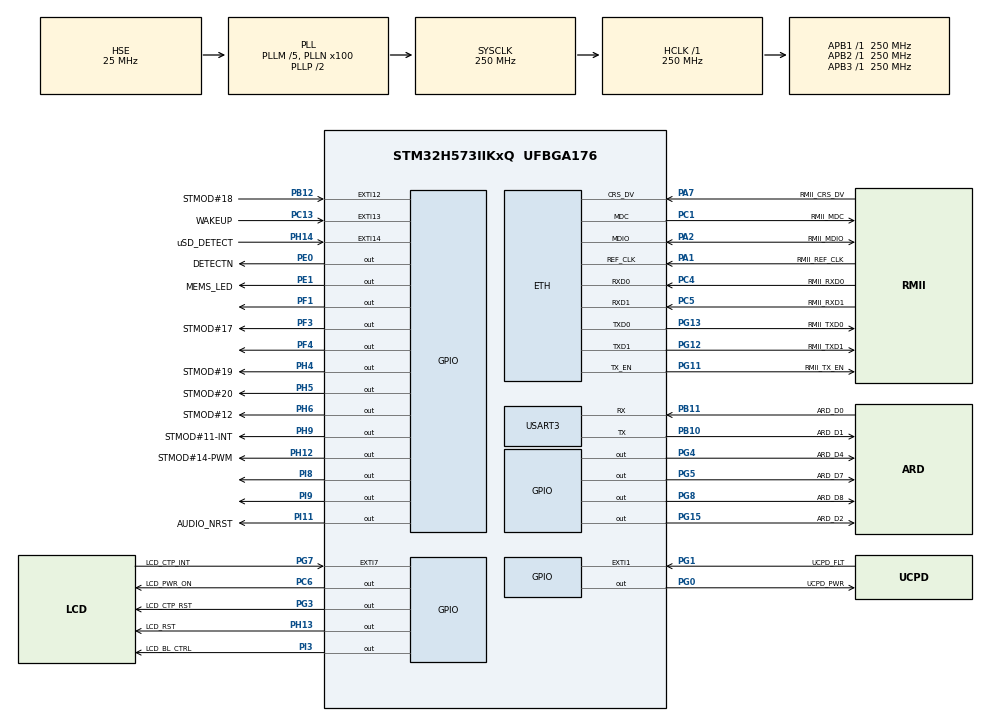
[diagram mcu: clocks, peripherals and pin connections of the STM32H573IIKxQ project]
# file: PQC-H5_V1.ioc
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AES.Algorithm=CRYP_AES_ECB
AES.KeySize=CRYP_KEYSIZE_256B
BOOTPATH.BootPathName=LEGACY
BOOTPATH.UserSelectedBootPath=LEGACY
CORTEX_M33_NS.userName=CORTEX_M33
ETH.MediaInterface=HAL_ETH_RMII_MODE
ETH.RxBuffLen=1536
HASH.Algorithm=HASH_ALGOSELECTION_SHA384
HASH.pKey=__NULL
Mcu.Family=STM32H5
Mcu.Name=STM32H573IIKxQ
Mcu.Package=UFBGA176
NETXDUO.ETH_ON=1
NETXDUO.LAN_8742=1
NETXDUO.NX_APP_MEM_POOL_SIZE=1024*100
NETXDUO.NX_APP_PACKET_POOL_SIZE=20
NETXDUO.NetXDuo_Generate_Init_Code=true
NVIC.PriorityGroup=NVIC_PRIORITYGROUP_4
NVIC.TIM6_IRQn=true\:15\:0\:false\:false\:true\:false\:false\:true\:true
NVIC.TimeBase=TIM6_IRQn
NVIC.TimeBaseIP=TIM6
NetXDuo.BSP.number=1
NetXDuo0.BSP.STBoard=false
NetXDuo0.BSP.api=BSP_COMPONENT_DRIVER
NetXDuo0.BSP.component=lan8742
NetXDuo0.BSP.instance=lan8742
NetXDuo0.BSP.name=LAN_Component
NetXDuo0.BSP.semaphore=SEMA_lan8742
NetXDuo0.BSP.solution=lan8742
PA0.GPIO_Label=ARD_A2
PA0.Signal=ADCx_INP0
PA1.GPIO_Label=RMII_REF_CLK
PA1.Mode=RMII
PA1.Signal=ETH_REF_CLK
PA10.Signal=USART1_RX
PA11.GPIO_Label=USB_FS_N
PA11.Signal=USB_DM
PA12.GPIO_Label=USB_FS_P
PA12.Signal=USB_DP
PA13(JTMS/SWDIO).GPIO_Label=JTMS
PA13(JTMS/SWDIO).Signal=DEBUG_JTMS-SWDIO
PA14(JTCK/SWCLK).GPIO_Label=JTCK
PA14(JTCK/SWCLK).Signal=DEBUG_JTCK-SWCLK
PA15(JTDI).GPIO_Label=JTDI
PA15(JTDI).Signal=DEBUG_JTDI
PA2.GPIO_Label=RMII_MDIO
PA2.Mode=RMII
PA2.Signal=ETH_MDIO
PA3.GPIO_Label=ARD_D10
PA3.Signal=SPI2_NSS
PA4.GPIO_Label=ARD_A1
PA4.Signal=ADCx_INP18
PA5.GPIO_Label=ARD_A3
PA5.Signal=ADCx_INP19
PA6.GPIO_Label=ARD_A4
PA6.Signal=ADCx_INP3
PA7.GPIO_Label=RMII_CRS_DV
PA7.Mode=RMII
PA7.Signal=ETH_CRS_DV
PA8.GPIO_Label=ARD_D9
PA8.Signal=S_TIM1_CH1
PA9.Signal=USART1_TX
PB0.GPIO_Label=ARD_A0
PB0.Signal=ADCx_INP9
PB1.GPIO_Mode=GPIO_MODE_AF_PP
PB1.GPIO_PuPd=GPIO_NOPULL
PB1.GPIO_Speed_High_Default=GPIO_SPEED_FREQ_VERY_HIGH
PB1.Signal=OCTOSPI1_IO0
PB10.GPIO_Label=ARD_D1
PB10.Mode=Asynchronous
PB10.Signal=USART3_TX
PB11.GPIO_Label=ARD_D0
PB11.Mode=Asynchronous
PB11.Signal=USART3_RX
PB12.GPIO_Label=STMOD\#18
PB12.Signal=GPXTI12
PB13.GPIO_Label=UCPD_CC1
PB13.Signal=UCPD1_CC1
PB14.GPIO_Label=UCPD_CC2
PB14.Signal=UCPD1_CC2
PB15.GPIO_Label=ARD_D11
PB15.Signal=SPI2_MOSI
PB2.Signal=OCTOSPI1_DQS
PB3(JTDO/TRACESWO).GPIO_Label=SWO
PB3(JTDO/TRACESWO).Signal=DEBUG_JTDO-SWO
PB5.GPIO_Label=ARD_D3
PB5.Signal=S_TIM3_CH2
PB6.GPIO_Label=I2C1_SCL
PB6.Signal=I2C1_SCL
PB7.GPIO_Label=I2C1_SDA
PB7.Signal=I2C1_SDA
PC0.Signal=OCTOSPI1_IO7
PC1.GPIO_Label=RMII_MDC
PC1.Mode=RMII
PC1.Signal=ETH_MDC
PC10.GPIO_Label=SDIO1_D2
PC10.Signal=SDMMC1_D2
PC11.GPIO_Label=SDIO1_D3
PC11.Signal=SDMMC1_D3
PC12.GPIO_Label=SDIO1_CK
PC12.Signal=SDMMC1_CK
PC13.GPIO_Label=WAKEUP
PC13.Signal=GPXTI13
PC14-OSC32_IN(OSC32_IN).Signal=RCC_OSC32_IN
PC15-OSC32_OUT(OSC32_OUT).Signal=RCC_OSC32_OUT
PC2.GPIO_Mode=GPIO_MODE_AF_PP
PC2.GPIO_PuPd=GPIO_NOPULL
PC2.GPIO_Speed_High_Default=GPIO_SPEED_FREQ_VERY_HIGH
PC2.Signal=OCTOSPI1_IO2
PC3.GPIO_Label=PDM_SAI1_SD3
PC3.Signal=SAI1_D3
PC4.GPIO_Label=RMII_RXD0
PC4.Mode=RMII
PC4.Signal=ETH_RXD0
PC5.GPIO_Label=RMII_RXD1
PC5.Mode=RMII
PC5.Signal=ETH_RXD1
PC6.GPIO_Label=LCD_PWR_ON
PC6.Signal=GPIO_Output
PC7.Signal=FMC_NE1
PC8.GPIO_Label=SDIO1_D0
PC8.Signal=SDMMC1_D0
PC9.GPIO_Label=SDIO1_D1
PC9.Signal=SDMMC1_D1
PD0.GPIO_Label=LCD_D2
PD0.Signal=FMC_D2_DA2
PD1.GPIO_Label=LCD_D3
PD1.Signal=FMC_D3_DA3
PD10.GPIO_Label=LCD_D15
PD10.Signal=FMC_D15_DA15
PD11.Signal=SAI1_CK1
PD12.GPIO_Mode=GPIO_MODE_AF_PP
PD12.GPIO_PuPd=GPIO_NOPULL
PD12.GPIO_Speed_High_Default=GPIO_SPEED_FREQ_VERY_HIGH
PD12.Signal=OCTOSPI1_IO1
PD13.GPIO_Mode=GPIO_MODE_AF_PP
PD13.GPIO_PuPd=GPIO_NOPULL
PD13.GPIO_Speed_High_Default=GPIO_SPEED_FREQ_VERY_HIGH
PD13.Signal=OCTOSPI1_IO3
PD14.GPIO_Label=LCD_D0
PD14.Signal=FMC_D0_DA0
PD15.GPIO_Label=LCD_D1
PD15.Signal=FMC_D1_DA1
PD2.GPIO_Label=SDIO1_CMD
PD2.Signal=SDMMC1_CMD
PD3.GPIO_Label=LCD_TE
PD3.Signal=FMC_CLK
PD4.GPIO_Label=LCD_NOE
PD4.Signal=FMC_NOE
PD5.GPIO_Label=LCD_NWE
PD5.Signal=FMC_NWE
PD6.Signal=SAI1_SD_A
PD8.GPIO_Label=LCD_D13
PD8.Signal=FMC_D13_DA13
PD9.GPIO_Label=LCD_D14
PD9.Signal=FMC_D14_DA14
PE0.GPIO_Label=DETECTN
PE0.Signal=GPIO_Output
PE1.GPIO_Label=MEMS_LED
PE1.Signal=GPIO_Output
PE10.GPIO_Label=LCD_D7
PE10.Signal=FMC_D7_DA7
PE11.GPIO_Label=LCD_D8
PE11.Signal=FMC_D8_DA8
PE12.GPIO_Label=LCD_D9
PE12.Signal=FMC_D9_DA9
PE13.GPIO_Label=LCD_D10
PE13.Signal=FMC_D10_DA10
PE14.GPIO_Label=LCD_D11
PE14.Signal=FMC_D11_DA11
PE15.GPIO_Label=LCD_D12
PE15.Signal=FMC_D12_DA12
PE2.Signal=DEBUG_TRACECLK
PE3.GPIO_Label=TRACED0
PE3.Signal=DEBUG_TRACED0
PE4.Signal=SAI1_D2
PE5.GPIO_Label=TRACED2
PE5.Signal=DEBUG_TRACED2
PE6.GPIO_Label=TRACED3
PE6.Signal=DEBUG_TRACED3
PE7.Signal=FMC_D4_DA4
PE8.GPIO_Label=LCD_D5
PE8.Signal=FMC_D5_DA5
PE9.GPIO_Label=LCD_D6
PE9.Signal=FMC_D6_DA6
PF0.GPIO_Label=LCD_A0_RS
PF0.Signal=FMC_A0
PF1.Signal=GPIO_Output
PF10.GPIO_Mode=GPIO_MODE_AF_PP
PF10.GPIO_PuPd=GPIO_NOPULL
PF10.GPIO_Speed_High_Default=GPIO_SPEED_FREQ_VERY_HIGH
PF10.Signal=OCTOSPI1_CLK
PF11.GPIO_Label=STMOD\#13
PF11.Signal=ADC1_INP2
PF12.GPIO_Label=ARD_A5
PF12.Signal=ADC1_INP6
PF13.GPIO_Label=IBUS_SENSE
PF13.Signal=ADC2_INP2
PF14.GPIO_Label=VBUS_SENSE
PF14.Signal=ADC2_INP6
PF3.GPIO_Label=STMOD\#17
PF3.Signal=GPIO_Output
PF4.Signal=GPIO_Output
PG0.GPIO_Label=UCPD_PWR
PG0.Signal=GPIO_Output
PG1.GPIO_Label=UCPD_FLT
PG1.Signal=GPXTI1
PG10.GPIO_Label=SAI2_SD_B
PG10.Signal=SAI2_SD_B
PG11.GPIO_Label=RMII_TX_EN
PG11.Mode=RMII
PG11.Signal=ETH_TX_EN
PG12.GPIO_Label=RMII_TXD1
PG12.Mode=RMII
PG12.Signal=ETH_TXD1
PG13.GPIO_Label=RMII_TXD0
PG13.Mode=RMII
PG13.Signal=ETH_TXD0
PG14.GPIO_Label=TRACED1
PG14.Signal=DEBUG_TRACED1
PG15.GPIO_Label=ARD_D2
PG15.Signal=GPIO_Output
PG3.GPIO_Label=LCD_CTP_RST
PG3.Signal=GPIO_Output
PG4.GPIO_Label=ARD_D4
PG4.Signal=GPIO_Output
PG5.GPIO_Label=ARD_D7
PG5.Signal=GPIO_Output
PG6.GPIO_Mode=GPIO_MODE_AF_PP
PG6.GPIO_PuPd=GPIO_NOPULL
PG6.GPIO_Speed_High_Default=GPIO_SPEED_FREQ_VERY_HIGH
PG6.Signal=OCTOSPI1_NCS
PG7.GPIO_Label=LCD_CTP_INT
PG7.Signal=GPXTI7
PG8.GPIO_Label=ARD_D8
PG8.Signal=GPIO_Output
PG9.GPIO_Mode=GPIO_MODE_AF_PP
PG9.GPIO_PuPd=GPIO_NOPULL
PG9.GPIO_Speed_High_Default=GPIO_SPEED_FREQ_VERY_HIGH
PG9.Signal=OCTOSPI1_IO6
PH0-OSC_IN(PH0).Mode=HSE-DIG-External-Clock-Source
PH0-OSC_IN(PH0).Signal=RCC_OSC_IN
PH10.GPIO_Label=ARD_D6
PH10.Signal=S_TIM5_CH1
PH11.GPIO_Label=ARD_D5
PH11.Signal=S_TIM5_CH2
PH12.GPIO_Label=STMOD\#14-PWM
PH12.Signal=GPIO_Output
PH13.GPIO_Label=LCD_RST
PH13.Signal=GPIO_Output
PH14.GPIO_Label=uSD_DETECT
PH14.Signal=GPXTI14
PH2.GPIO_Mode=GPIO_MODE_AF_PP
PH2.GPIO_PuPd=GPIO_NOPULL
PH2.GPIO_Speed_High_Default=GPIO_SPEED_FREQ_VERY_HIGH
PH2.Signal=OCTOSPI1_IO4
PH3.GPIO_Mode=GPIO_MODE_AF_PP
PH3.GPIO_PuPd=GPIO_NOPULL
PH3.GPIO_Speed_High_Default=GPIO_SPEED_FREQ_VERY_HIGH
PH3.Signal=OCTOSPI1_IO5
PH4.GPIO_Label=STMOD\#19
PH4.Signal=GPIO_Output
PH5.GPIO_Label=STMOD\#20
PH5.Signal=GPIO_Output
PH6.GPIO_Label=STMOD\#12
PH6.Signal=GPIO_Output
PH7.GPIO_Label=STMOD\#12-RST
PH7.Signal=SPI5_MISO
PH8.GPIO_Label=STMOD\#9-MISOs
PH8.Signal=SPI5_MOSI
PH9.GPIO_Label=STMOD\#11-INT
PH9.Signal=GPIO_Output
PI1.GPIO_Label=ARD_D13
PI1.Signal=SPI2_SCK
PI10.GPIO_Label=RMII_RX_ER
PI10.Signal=ETH_RX_ER
PI11.GPIO_Label=AUDIO_NRST
PI11.Signal=GPIO_Output
PI2.GPIO_Label=ARD_D12
PI2.Signal=SPI2_MISO
PI3.GPIO_Label=LCD_BL_CTRL
PI3.Signal=GPIO_Output
PI4.GPIO_Label=SAI2_MCLK_A
PI4.Signal=SAI2_MCLK_A
PI5.GPIO_Label=SAI2_SCK_A
PI5.Signal=SAI2_SCK_A
PI6.GPIO_Label=SAI2_SD_A
PI6.Signal=SAI2_SD_A
PI7.GPIO_Label=SAI2_FS_A
PI7.Signal=SAI2_FS_A
PI8.Signal=GPIO_Output
PI9.Signal=GPIO_Output
ProjectManager.HeapSize=0x800
ProjectManager.StackSize=0x1000
ProjectManager.TargetToolchain=STM32CubeIDE
RCC.ADCFreq_Value=250000000
RCC.AHBFreq_Value=250000000
RCC.APB1Freq_Value=250000000
RCC.APB1TimFreq_Value=250000000
RCC.APB2Freq_Value=250000000
RCC.APB2TimFreq_Value=250000000
RCC.APB3Freq_Value=250000000
RCC.CSI_VALUE=4000000
RCC.CortexFreq_Value=250000000
RCC.EPOD_VALUE=25000000
RCC.HCLKFreq_Value=250000000
RCC.HSE_VALUE=25000000
RCC.HSI48_VALUE=48000000
RCC.HSIDiv=RCC_HSI_DIV1
RCC.HSI_VALUE=64000000
RCC.LSE_VALUE=32768
RCC.LSIRC_VALUE=32000
RCC.PLL2FRACN=0
RCC.PLL2N=32
RCC.PLL2P=1
RCC.PLLM=5
RCC.PLLN=100
RCC.PLLSourceVirtual=RCC_PLL1_SOURCE_HSE
RCC.SYSCLKFreq_VALUE=250000000
RCC.SYSCLKSource=RCC_SYSCLKSOURCE_PLLCLK
RCC.USBFreq_Value=48000000
RCC.VCOOutputFreq_Value=500000000
SH.ADCx_INP0.0=ADC1_INP0
SH.ADCx_INP18.0=ADC1_INP18
SH.ADCx_INP19.0=ADC1_INP19
SH.ADCx_INP3.0=ADC1_INP3
SH.ADCx_INP9.0=ADC1_INP9
SH.FMC_A0.0=FMC_A0
SH.FMC_CLK.0=FMC_CLK
SH.FMC_D0_DA0.0=FMC_D0
SH.FMC_D10_DA10.0=FMC_D10
SH.FMC_D11_DA11.0=FMC_D11
SH.FMC_D12_DA12.0=FMC_D12
SH.FMC_D13_DA13.0=FMC_D13
SH.FMC_D14_DA14.0=FMC_D14
SH.FMC_D15_DA15.0=FMC_D15
SH.FMC_D1_DA1.0=FMC_D1
SH.FMC_D2_DA2.0=FMC_D2
SH.FMC_D3_DA3.0=FMC_D3
SH.FMC_D4_DA4.0=FMC_D4
SH.FMC_D5_DA5.0=FMC_D5
SH.FMC_D6_DA6.0=FMC_D6
SH.FMC_D7_DA7.0=FMC_D7
SH.FMC_D8_DA8.0=FMC_D8
SH.FMC_D9_DA9.0=FMC_D9
SH.FMC_NOE.0=FMC_NOE
SH.FMC_NWE.0=FMC_NWE
SH.S_TIM1_CH1.0=TIM1_CH1
SH.S_TIM3_CH2.0=TIM3_CH2
SH.S_TIM5_CH1.0=TIM5_CH1
SH.S_TIM5_CH2.0=TIM5_CH2
STM32H573I-DK.LD1=true
STM32H573I-DK.LD2=true
STM32H573I-DK.LD3=true
STM32H573I-DK.LD4=true
STM32H573I-DK.VCP=true
STMicroelectronics.X-CUBE-FREERTOS.1.3.1.configTOTAL_HEAP_SIZE=50000
THREADX.TX_APP_CREATION=1
THREADX.TX_APP_GENERATE_INIT_CODE=true
THREADX.TX_APP_MEM_POOL_SIZE=1024*10
THREADX.TX_APP_STACK_SIZE=1024
USART3.VirtualMode-Asynchronous=VM_ASYNC
VP_AES_VS_AES.Mode=AES_Activate
VP_BOOTPATH_VS_BOOTPATH.Mode=BP_Activate
VP_CORTEX_M33_NS_VS_Hclk.Mode=Hclk_Mode
VP_HASH_VS_HASH.Mode=HASH_Activate
VP_ICACHE_VS_ENABLE_ICACHE_MEMORY.Mode=Memoryregions
VP_ICACHE_VS_ICACHE.Mode=DefaultMode
VP_MEMORYMAP_VS_MEMORYMAP.Mode=CurAppReg
VP_NETXDUO_VS_AddonsOoDHCP.Mode=Addons_DHCP_Client
VP_NETXDUO_VS_EthernetOoPhyOoInterface.Mode=LAN8742_Phy_Interface
VP_NETXDUO_VS_NXOoCore.Mode=NX_Core
VP_NETXDUO_VS_NetworkOoInterface.Mode=Ethernet_Interface
VP_PWR_VS_LPOM.Mode=PowerOptimisation
VP_PWR_VS_SECSignals.Mode=Security/Privilege
VP_RNG_VS_RNG.Mode=RNG_Activate
VP_RTC_VS_RTC_Activate.Mode=RTC_Enabled
VP_RTC_VS_RTC_Calendar.Mode=RTC_Calendar
VP_STM32H573I-DK_VS_BSP_COMMON.Mode=COMMON
VP_SYS_VS_tim6.Mode=TIM6
VP_THREADX_VS_RTOSJjThreadXJjCoreJjDefault.Mode=Core_Default
VP_wolfSSL.I-CUBE-wolfSSL_VS_wolfSSLJjwolfSSL_5.8.0_5.8.0.Mode=wolfSSLJjwolfSSL
board=STM32H573I-DK
wolfSSL.I-CUBE-wolfSSL.5.8.0.WOLF_CONF_KYBER=1
wolfSSL.I-CUBE-wolfSSL.5.8.0.WOLF_CONF_MATH=4
wolfSSL.I-CUBE-wolfSSL.5.8.0.WOLF_CONF_SHA2_384=1
wolfSSL.I-CUBE-wolfSSL.5.8.0.WOLF_CONF_SHA2_512=1
wolfSSL.I-CUBE-wolfSSL.5.8.0.WOLF_CONF_SHA3=1
wolfSSL.I-CUBE-wolfSSL.5.8.0.wolfSSLCcwolfSSLJjwolfCryptJjCore=true
wolfSSL.I-CUBE-wolfSSL.5.8.0.wolfSSLCcwolfSSLJjwolfCryptJjTest=true
wolfSSL.I-CUBE-wolfSSL.5.8.0.wolfSSLCcwolfSSLJjwolfSSLJjCore=true

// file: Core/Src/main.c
/* USER CODE BEGIN Header */
/**
  ******************************************************************************
  * @file           : main.c
  * @brief          : Main program body
  ******************************************************************************
  * @attention
  *
  * Copyright (c) 2025 STMicroelectronics.
  * All rights reserved.
  *
  * This software is licensed under terms that can be found in the LICENSE file
  * in the root directory of this software component.
  * If no LICENSE file comes with this software, it is provided AS-IS.
  *
  ******************************************************************************
  */
/* USER CODE END Header */
#include "app_threadx.h"
#include "main.h"

/* USER CODE BEGIN Includes */
#include "wolfssl/wolfcrypt/settings.h"
//#include "wolfssl_example.h"
/* USER CODE END Includes */

ETH_DMADescTypeDef  DMARxDscrTab[ETH_RX_DESC_CNT]; /* Ethernet Rx DMA Descriptors */
ETH_DMADescTypeDef  DMATxDscrTab[ETH_TX_DESC_CNT]; /* Ethernet Tx DMA Descriptors */

COM_InitTypeDef BspCOMInit;
CRYP_HandleTypeDef hcryp;
uint32_t pKeyAES[8] = {0x00000000,0x00000000,0x00000000,0x00000000,0x00000000,0x00000000,0x00000000,0x00000000};

ETH_HandleTypeDef heth;

HASH_HandleTypeDef hhash;

RNG_HandleTypeDef hrng;

RTC_HandleTypeDef hrtc;

UART_HandleTypeDef huart3;

/* USER CODE BEGIN PV */
__ALIGN_BEGIN static const uint32_t pKeyCRYP[6] __ALIGN_END = {
            0x00000000,0x00000000,0x00000000,0x00000000,0x00000000,0x00000000};
/* USER CODE END PV */

void SystemClock_Config(void);
static void MX_GPIO_Init(void);
static void MX_ICACHE_Init(void);
static void MX_RNG_Init(void);
static void MX_RTC_Init(void);
static void MX_HASH_Init(void);
static void MX_AES_Init(void);
static void MX_USART3_UART_Init(void);
static void MX_ETH_Init(void);

int main(void)
{

  /* MCU Configuration--------------------------------------------------------*/

  /* Reset of all peripherals, Initializes the Flash interface and the Systick. */
  HAL_Init();

  /* USER CODE BEGIN Init */
  setvbuf(stdin, NULL, _IONBF, 0);
  setvbuf(stdout, NULL, _IONBF, 0);
  setvbuf(stderr, NULL, _IONBF, 0);
  /* USER CODE END Init */

  /* Configure the system clock */
  SystemClock_Config();

  /* Initialize all configured peripherals */
  MX_GPIO_Init();
  MX_ICACHE_Init();
  MX_RNG_Init();
  MX_RTC_Init();
  MX_HASH_Init();
  MX_AES_Init();
  MX_USART3_UART_Init();
  MX_ETH_Init();

  /* Initialize leds */
  BSP_LED_Init(LED_GREEN);
  BSP_LED_Init(LED_ORANGE);
  BSP_LED_Init(LED_RED);
  BSP_LED_Init(LED_BLUE);

  /* Initialize COM1 port (115200, 8 bits (7-bit data + 1 stop bit), no parity */
  BspCOMInit.BaudRate   = 115200;
  BspCOMInit.WordLength = COM_WORDLENGTH_8B;
  BspCOMInit.StopBits   = COM_STOPBITS_1;
  BspCOMInit.Parity     = COM_PARITY_NONE;
  BspCOMInit.HwFlowCtl  = COM_HWCONTROL_NONE;
  if (BSP_COM_Init(COM1, &BspCOMInit) != BSP_ERROR_NONE)
  {
    Error_Handler();
  }

  MX_ThreadX_Init();

  /* We should never get here as control is now taken by the scheduler */

  /* Infinite loop */
  while (1)
  {

  }
}

void SystemClock_Config(void)
{
  RCC_OscInitTypeDef RCC_OscInitStruct = {0};
  RCC_ClkInitTypeDef RCC_ClkInitStruct = {0};

  /** Configure the main internal regulator output voltage
  */
  __HAL_PWR_VOLTAGESCALING_CONFIG(PWR_REGULATOR_VOLTAGE_SCALE0);

  while(!__HAL_PWR_GET_FLAG(PWR_FLAG_VOSRDY)) {}

  /** Initializes the RCC Oscillators according to the specified parameters
  * in the RCC_OscInitTypeDef structure.
  */
  RCC_OscInitStruct.OscillatorType = RCC_OSCILLATORTYPE_HSI48|RCC_OSCILLATORTYPE_LSI
                              |RCC_OSCILLATORTYPE_HSE;
  RCC_OscInitStruct.HSEState = RCC_HSE_BYPASS_DIGITAL;
  RCC_OscInitStruct.LSIState = RCC_LSI_ON;
  RCC_OscInitStruct.HSI48State = RCC_HSI48_ON;
  RCC_OscInitStruct.PLL.PLLState = RCC_PLL_ON;
  RCC_OscInitStruct.PLL.PLLSource = RCC_PLL1_SOURCE_HSE;
  RCC_OscInitStruct.PLL.PLLM = 5;
  RCC_OscInitStruct.PLL.PLLN = 100;
  RCC_OscInitStruct.PLL.PLLP = 2;
  RCC_OscInitStruct.PLL.PLLQ = 2;
  RCC_OscInitStruct.PLL.PLLR = 2;
  RCC_OscInitStruct.PLL.PLLRGE = RCC_PLL1_VCIRANGE_2;
  RCC_OscInitStruct.PLL.PLLVCOSEL = RCC_PLL1_VCORANGE_WIDE;
  RCC_OscInitStruct.PLL.PLLFRACN = 0;
  if (HAL_RCC_OscConfig(&RCC_OscInitStruct) != HAL_OK)
  {
    Error_Handler();
  }

  /** Initializes the CPU, AHB and APB buses clocks
  */
  RCC_ClkInitStruct.ClockType = RCC_CLOCKTYPE_HCLK|RCC_CLOCKTYPE_SYSCLK
                              |RCC_CLOCKTYPE_PCLK1|RCC_CLOCKTYPE_PCLK2
                              |RCC_CLOCKTYPE_PCLK3;
  RCC_ClkInitStruct.SYSCLKSource = RCC_SYSCLKSOURCE_PLLCLK;
  RCC_ClkInitStruct.AHBCLKDivider = RCC_SYSCLK_DIV1;
  RCC_ClkInitStruct.APB1CLKDivider = RCC_HCLK_DIV1;
  RCC_ClkInitStruct.APB2CLKDivider = RCC_HCLK_DIV1;
  RCC_ClkInitStruct.APB3CLKDivider = RCC_HCLK_DIV1;

  if (HAL_RCC_ClockConfig(&RCC_ClkInitStruct, FLASH_LATENCY_5) != HAL_OK)
  {
    Error_Handler();
  }

  /** Configure the programming delay
  */
  __HAL_FLASH_SET_PROGRAM_DELAY(FLASH_PROGRAMMING_DELAY_2);
}

static void MX_AES_Init(void)
{

  hcryp.Instance = AES;
  hcryp.Init.DataType = CRYP_NO_SWAP;
  hcryp.Init.KeySize = CRYP_KEYSIZE_256B;
  hcryp.Init.pKey = (uint32_t *)pKeyAES;
  hcryp.Init.Algorithm = CRYP_AES_ECB;
  hcryp.Init.DataWidthUnit = CRYP_DATAWIDTHUNIT_WORD;
  hcryp.Init.HeaderWidthUnit = CRYP_HEADERWIDTHUNIT_WORD;
  hcryp.Init.KeyIVConfigSkip = CRYP_KEYIVCONFIG_ALWAYS;
  hcryp.Init.KeyMode = CRYP_KEYMODE_NORMAL;
  if (HAL_CRYP_Init(&hcryp) != HAL_OK)
  {
    Error_Handler();
  }

}

static void MX_ETH_Init(void)
{

   static uint8_t MACAddr[6];

  heth.Instance = ETH;
  MACAddr[0] = 0x00;
  MACAddr[1] = 0x80;
  MACAddr[2] = 0xE1;
  MACAddr[3] = 0x00;
  MACAddr[4] = 0x00;
  MACAddr[5] = 0x00;
  heth.Init.MACAddr = &MACAddr[0];
  heth.Init.MediaInterface = HAL_ETH_RMII_MODE;
  heth.Init.TxDesc = DMATxDscrTab;
  heth.Init.RxDesc = DMARxDscrTab;
  heth.Init.RxBuffLen = 1536;

  if (HAL_ETH_Init(&heth) != HAL_OK)
  {
    Error_Handler();
  }

}

static void MX_HASH_Init(void)
{

  hhash.Instance = HASH;
  hhash.Init.DataType = HASH_NO_SWAP;
  hhash.Init.Algorithm = HASH_ALGOSELECTION_SHA384;
  if (HAL_HASH_Init(&hhash) != HAL_OK)
  {
    Error_Handler();
  }

}

static void MX_ICACHE_Init(void)
{

  /** Enable instruction cache (default 2-ways set associative cache)
  */
  if (HAL_ICACHE_Enable() != HAL_OK)
  {
    Error_Handler();
  }

}

static void MX_RNG_Init(void)
{

  hrng.Instance = RNG;
  hrng.Init.ClockErrorDetection = RNG_CED_ENABLE;
  if (HAL_RNG_Init(&hrng) != HAL_OK)
  {
    Error_Handler();
  }

}

static void MX_RTC_Init(void)
{

  RTC_PrivilegeStateTypeDef privilegeState = {0};
  RTC_TimeTypeDef sTime = {0};
  RTC_DateTypeDef sDate = {0};

  /** Initialize RTC Only
  */
  hrtc.Instance = RTC;
  hrtc.Init.HourFormat = RTC_HOURFORMAT_24;
  hrtc.Init.AsynchPrediv = 127;
  hrtc.Init.SynchPrediv = 255;
  hrtc.Init.OutPut = RTC_OUTPUT_DISABLE;
  hrtc.Init.OutPutRemap = RTC_OUTPUT_REMAP_NONE;
  hrtc.Init.OutPutPolarity = RTC_OUTPUT_POLARITY_HIGH;
  hrtc.Init.OutPutType = RTC_OUTPUT_TYPE_OPENDRAIN;
  hrtc.Init.OutPutPullUp = RTC_OUTPUT_PULLUP_NONE;
  hrtc.Init.BinMode = RTC_BINARY_NONE;
  if (HAL_RTC_Init(&hrtc) != HAL_OK)
  {
    Error_Handler();
  }
  privilegeState.rtcPrivilegeFull = RTC_PRIVILEGE_FULL_NO;
  privilegeState.backupRegisterPrivZone = RTC_PRIVILEGE_BKUP_ZONE_NONE;
  privilegeState.backupRegisterStartZone2 = RTC_BKP_DR0;
  privilegeState.backupRegisterStartZone3 = RTC_BKP_DR0;
  if (HAL_RTCEx_PrivilegeModeSet(&hrtc, &privilegeState) != HAL_OK)
  {
    Error_Handler();
  }

  /** Initialize RTC and set the Time and Date
  */
  sTime.Hours = 0x0;
  sTime.Minutes = 0x0;
  sTime.Seconds = 0x0;
  sTime.DayLightSaving = RTC_DAYLIGHTSAVING_NONE;
  sTime.StoreOperation = RTC_STOREOPERATION_RESET;
  if (HAL_RTC_SetTime(&hrtc, &sTime, RTC_FORMAT_BCD) != HAL_OK)
  {
    Error_Handler();
  }
  sDate.WeekDay = RTC_WEEKDAY_MONDAY;
  sDate.Month = RTC_MONTH_JANUARY;
  sDate.Date = 0x1;
  sDate.Year = 0x0;

  if (HAL_RTC_SetDate(&hrtc, &sDate, RTC_FORMAT_BCD) != HAL_OK)
  {
    Error_Handler();
  }

}

static void MX_USART3_UART_Init(void)
{

  huart3.Instance = USART3;
  huart3.Init.BaudRate = 115200;
  huart3.Init.WordLength = UART_WORDLENGTH_8B;
  huart3.Init.StopBits = UART_STOPBITS_1;
  huart3.Init.Parity = UART_PARITY_NONE;
  huart3.Init.Mode = UART_MODE_TX_RX;
  huart3.Init.HwFlowCtl = UART_HWCONTROL_NONE;
  huart3.Init.OverSampling = UART_OVERSAMPLING_16;
  huart3.Init.OneBitSampling = UART_ONE_BIT_SAMPLE_DISABLE;
  huart3.Init.ClockPrescaler = UART_PRESCALER_DIV1;
  huart3.AdvancedInit.AdvFeatureInit = UART_ADVFEATURE_NO_INIT;
  if (HAL_UART_Init(&huart3) != HAL_OK)
  {
    Error_Handler();
  }
  if (HAL_UARTEx_SetTxFifoThreshold(&huart3, UART_TXFIFO_THRESHOLD_1_8) != HAL_OK)
  {
    Error_Handler();
  }
  if (HAL_UARTEx_SetRxFifoThreshold(&huart3, UART_RXFIFO_THRESHOLD_1_8) != HAL_OK)
  {
    Error_Handler();
  }
  if (HAL_UARTEx_DisableFifoMode(&huart3) != HAL_OK)
  {
    Error_Handler();
  }

}

static void MX_GPIO_Init(void)
{
  GPIO_InitTypeDef GPIO_InitStruct = {0};

  /* GPIO Ports Clock Enable */
  __HAL_RCC_GPIOI_CLK_ENABLE();
  __HAL_RCC_GPIOB_CLK_ENABLE();
  __HAL_RCC_GPIOG_CLK_ENABLE();
  __HAL_RCC_GPIOD_CLK_ENABLE();
  __HAL_RCC_GPIOE_CLK_ENABLE();
  __HAL_RCC_GPIOA_CLK_ENABLE();
  __HAL_RCC_GPIOH_CLK_ENABLE();
  __HAL_RCC_GPIOC_CLK_ENABLE();
  __HAL_RCC_GPIOF_CLK_ENABLE();

  /*Configure GPIO pin Output Level */
  HAL_GPIO_WritePin(GPIOG, ARD_D2_Pin|ARD_D8_Pin|LCD_CTP_RST_Pin|ARD_D7_Pin
                          |ARD_D4_Pin|UCPD_PWR_Pin, GPIO_PIN_RESET);

  /*Configure GPIO pin Output Level */
  HAL_GPIO_WritePin(GPIOI, LCD_BL_CTRL_Pin|GPIO_PIN_9|GPIO_PIN_8|AUDIO_NRST_Pin, GPIO_PIN_RESET);

  /*Configure GPIO pin Output Level */
  HAL_GPIO_WritePin(GPIOE, MEMS_LED_Pin|DETECTN_Pin, GPIO_PIN_RESET);

  /*Configure GPIO pin Output Level */
  HAL_GPIO_WritePin(GPIOH, LCD_RST_Pin|STMOD_11_INT_Pin|STMOD_14_PWM_Pin|STMOD_20_Pin
                          |STMOD_12_Pin|STMOD_19_Pin, GPIO_PIN_RESET);

  /*Configure GPIO pin Output Level */
  HAL_GPIO_WritePin(GPIOF, GPIO_PIN_1|GPIO_PIN_4|STMOD_17_Pin, GPIO_PIN_RESET);

  /*Configure GPIO pin Output Level */
  HAL_GPIO_WritePin(LCD_PWR_ON_GPIO_Port, LCD_PWR_ON_Pin, GPIO_PIN_RESET);

  /*Configure GPIO pins : SAI2_FS_A_Pin SAI2_SCK_A_Pin SAI2_MCLK_A_Pin SAI2_SD_A_Pin */
  GPIO_InitStruct.Pin = SAI2_FS_A_Pin|SAI2_SCK_A_Pin|SAI2_MCLK_A_Pin|SAI2_SD_A_Pin;
  GPIO_InitStruct.Mode = GPIO_MODE_AF_PP;
  GPIO_InitStruct.Pull = GPIO_NOPULL;
  GPIO_InitStruct.Speed = GPIO_SPEED_FREQ_LOW;
  GPIO_InitStruct.Alternate = GPIO_AF10_SAI2;
  HAL_GPIO_Init(GPIOI, &GPIO_InitStruct);

  /*Configure GPIO pin : ARD_D3_Pin */
  GPIO_InitStruct.Pin = ARD_D3_Pin;
  GPIO_InitStruct.Mode = GPIO_MODE_AF_PP;
  GPIO_InitStruct.Pull = GPIO_NOPULL;
  GPIO_InitStruct.Speed = GPIO_SPEED_FREQ_LOW;
  GPIO_InitStruct.Alternate = GPIO_AF2_TIM3;
  HAL_GPIO_Init(ARD_D3_GPIO_Port, &GPIO_InitStruct);

  /*Configure GPIO pins : ARD_D2_Pin ARD_D8_Pin LCD_CTP_RST_Pin ARD_D7_Pin
                           ARD_D4_Pin UCPD_PWR_Pin */
  GPIO_InitStruct.Pin = ARD_D2_Pin|ARD_D8_Pin|LCD_CTP_RST_Pin|ARD_D7_Pin
                          |ARD_D4_Pin|UCPD_PWR_Pin;
  GPIO_InitStruct.Mode = GPIO_MODE_OUTPUT_PP;
  GPIO_InitStruct.Pull = GPIO_NOPULL;
  GPIO_InitStruct.Speed = GPIO_SPEED_FREQ_LOW;
  HAL_GPIO_Init(GPIOG, &GPIO_InitStruct);

  /*Configure GPIO pin : SAI2_SD_B_Pin */
  GPIO_InitStruct.Pin = SAI2_SD_B_Pin;
  GPIO_InitStruct.Mode = GPIO_MODE_AF_PP;
  GPIO_InitStruct.Pull = GPIO_NOPULL;
  GPIO_InitStruct.Speed = GPIO_SPEED_FREQ_LOW;
  GPIO_InitStruct.Alternate = GPIO_AF10_SAI2;
  HAL_GPIO_Init(SAI2_SD_B_GPIO_Port, &GPIO_InitStruct);

  /*Configure GPIO pins : LCD_NWE_Pin LCD_TE_Pin LCD_D3_Pin LCD_NOE_Pin
                           LCD_D2_Pin LCD_D1_Pin LCD_D15_Pin LCD_D0_Pin
                           LCD_D14_Pin LCD_D13_Pin */
  GPIO_InitStruct.Pin = LCD_NWE_Pin|LCD_TE_Pin|LCD_D3_Pin|LCD_NOE_Pin
                          |LCD_D2_Pin|LCD_D1_Pin|LCD_D15_Pin|LCD_D0_Pin
                          |LCD_D14_Pin|LCD_D13_Pin;
  GPIO_InitStruct.Mode = GPIO_MODE_AF_PP;
  GPIO_InitStruct.Pull = GPIO_NOPULL;
  GPIO_InitStruct.Speed = GPIO_SPEED_FREQ_VERY_HIGH;
  GPIO_InitStruct.Alternate = GPIO_AF12_FMC;
  HAL_GPIO_Init(GPIOD, &GPIO_InitStruct);

  /*Configure GPIO pins : LCD_BL_CTRL_Pin PI9 PI8 AUDIO_NRST_Pin */
  GPIO_InitStruct.Pin = LCD_BL_CTRL_Pin|GPIO_PIN_9|GPIO_PIN_8|AUDIO_NRST_Pin;
  GPIO_InitStruct.Mode = GPIO_MODE_OUTPUT_PP;
  GPIO_InitStruct.Pull = GPIO_NOPULL;
  GPIO_InitStruct.Speed = GPIO_SPEED_FREQ_LOW;
  HAL_GPIO_Init(GPIOI, &GPIO_InitStruct);

  /*Configure GPIO pins : ARD_D13_Pin ARD_D12_Pin */
  GPIO_InitStruct.Pin = ARD_D13_Pin|ARD_D12_Pin;
  GPIO_InitStruct.Mode = GPIO_MODE_AF_PP;
  GPIO_InitStruct.Pull = GPIO_NOPULL;
  GPIO_InitStruct.Speed = GPIO_SPEED_FREQ_LOW;
  GPIO_InitStruct.Alternate = GPIO_AF5_SPI2;
  HAL_GPIO_Init(GPIOI, &GPIO_InitStruct);

  /*Configure GPIO pins : MEMS_LED_Pin DETECTN_Pin */
  GPIO_InitStruct.Pin = MEMS_LED_Pin|DETECTN_Pin;
  GPIO_InitStruct.Mode = GPIO_MODE_OUTPUT_PP;
  GPIO_InitStruct.Pull = GPIO_NOPULL;
  GPIO_InitStruct.Speed = GPIO_SPEED_FREQ_LOW;
  HAL_GPIO_Init(GPIOE, &GPIO_InitStruct);

  /*Configure GPIO pins : I2C1_SCL_Pin I2C1_SDA_Pin */
  GPIO_InitStruct.Pin = I2C1_SCL_Pin|I2C1_SDA_Pin;
  GPIO_InitStruct.Mode = GPIO_MODE_AF_OD;
  GPIO_InitStruct.Pull = GPIO_NOPULL;
  GPIO_InitStruct.Speed = GPIO_SPEED_FREQ_LOW;
  GPIO_InitStruct.Alternate = GPIO_AF4_I2C1;
  HAL_GPIO_Init(GPIOB, &GPIO_InitStruct);

  /*Configure GPIO pin : PG9 */
  GPIO_InitStruct.Pin = GPIO_PIN_9;
  GPIO_InitStruct.Mode = GPIO_MODE_AF_PP;
  GPIO_InitStruct.Pull = GPIO_NOPULL;
  GPIO_InitStruct.Speed = GPIO_SPEED_FREQ_VERY_HIGH;
  GPIO_InitStruct.Alternate = GPIO_AF9_OCTOSPI1;
  HAL_GPIO_Init(GPIOG, &GPIO_InitStruct);

  /*Configure GPIO pin : PD6 */
  GPIO_InitStruct.Pin = GPIO_PIN_6;
  GPIO_InitStruct.Mode = GPIO_MODE_AF_PP;
  GPIO_InitStruct.Pull = GPIO_NOPULL;
  GPIO_InitStruct.Speed = GPIO_SPEED_FREQ_LOW;
  GPIO_InitStruct.Alternate = GPIO_AF6_SAI1;
  HAL_GPIO_Init(GPIOD, &GPIO_InitStruct);

  /*Configure GPIO pins : LCD_RST_Pin STMOD_11_INT_Pin STMOD_14_PWM_Pin STMOD_20_Pin
                           STMOD_12_Pin STMOD_19_Pin */
  GPIO_InitStruct.Pin = LCD_RST_Pin|STMOD_11_INT_Pin|STMOD_14_PWM_Pin|STMOD_20_Pin
                          |STMOD_12_Pin|STMOD_19_Pin;
  GPIO_InitStruct.Mode = GPIO_MODE_OUTPUT_PP;
  GPIO_InitStruct.Pull = GPIO_NOPULL;
  GPIO_InitStruct.Speed = GPIO_SPEED_FREQ_LOW;
  HAL_GPIO_Init(GPIOH, &GPIO_InitStruct);

  /*Configure GPIO pin : PE4 */
  GPIO_InitStruct.Pin = GPIO_PIN_4;
  GPIO_InitStruct.Mode = GPIO_MODE_AF_PP;
  GPIO_InitStruct.Pull = GPIO_NOPULL;
  GPIO_InitStruct.Speed = GPIO_SPEED_FREQ_LOW;
  GPIO_InitStruct.Alternate = GPIO_AF2_SAI1;
  HAL_GPIO_Init(GPIOE, &GPIO_InitStruct);

  /*Configure GPIO pin : SDIO1_CMD_Pin */
  GPIO_InitStruct.Pin = SDIO1_CMD_Pin;
  GPIO_InitStruct.Mode = GPIO_MODE_AF_PP;
  GPIO_InitStruct.Pull = GPIO_NOPULL;
  GPIO_InitStruct.Speed = GPIO_SPEED_FREQ_HIGH;
  GPIO_InitStruct.Alternate = GPIO_AF12_SDMMC1;
  HAL_GPIO_Init(SDIO1_CMD_GPIO_Port, &GPIO_InitStruct);

  /*Configure GPIO pins : SDIO1_CK_Pin SDIO1_D3_Pin SDIO1_D2_Pin SDIO1_D1_Pin
                           SDIO1_D0_Pin */
  GPIO_InitStruct.Pin = SDIO1_CK_Pin|SDIO1_D3_Pin|SDIO1_D2_Pin|SDIO1_D1_Pin
                          |SDIO1_D0_Pin;
  GPIO_InitStruct.Mode = GPIO_MODE_AF_PP;
  GPIO_InitStruct.Pull = GPIO_NOPULL;
  GPIO_InitStruct.Speed = GPIO_SPEED_FREQ_HIGH;
  GPIO_InitStruct.Alternate = GPIO_AF12_SDMMC1;
  HAL_GPIO_Init(GPIOC, &GPIO_InitStruct);

  /*Configure GPIO pins : USB_FS_P_Pin USB_FS_N_Pin */
  GPIO_InitStruct.Pin = USB_FS_P_Pin|USB_FS_N_Pin;
  GPIO_InitStruct.Mode = GPIO_MODE_AF_PP;
  GPIO_InitStruct.Pull = GPIO_NOPULL;
  GPIO_InitStruct.Speed = GPIO_SPEED_FREQ_LOW;
  GPIO_InitStruct.Alternate = GPIO_AF10_USB;
  HAL_GPIO_Init(GPIOA, &GPIO_InitStruct);

  /*Configure GPIO pin : uSD_DETECT_Pin */
  GPIO_InitStruct.Pin = uSD_DETECT_Pin;
  GPIO_InitStruct.Mode = GPIO_MODE_IT_RISING;
  GPIO_InitStruct.Pull = GPIO_NOPULL;
  HAL_GPIO_Init(uSD_DETECT_GPIO_Port, &GPIO_InitStruct);

  /*Configure GPIO pin : WAKEUP_Pin */
  GPIO_InitStruct.Pin = WAKEUP_Pin;
  GPIO_InitStruct.Mode = GPIO_MODE_IT_RISING;
  GPIO_InitStruct.Pull = GPIO_NOPULL;
  HAL_GPIO_Init(WAKEUP_GPIO_Port, &GPIO_InitStruct);

  /*Configure GPIO pins : PA10 PA9 */
  GPIO_InitStruct.Pin = GPIO_PIN_10|GPIO_PIN_9;
  GPIO_InitStruct.Mode = GPIO_MODE_AF_PP;
  GPIO_InitStruct.Pull = GPIO_NOPULL;
  GPIO_InitStruct.Speed = GPIO_SPEED_FREQ_LOW;
  GPIO_InitStruct.Alternate = GPIO_AF7_USART1;
  HAL_GPIO_Init(GPIOA, &GPIO_InitStruct);

  /*Configure GPIO pins : PF1 PF4 STMOD_17_Pin */
  GPIO_InitStruct.Pin = GPIO_PIN_1|GPIO_PIN_4|STMOD_17_Pin;
  GPIO_InitStruct.Mode = GPIO_MODE_OUTPUT_PP;
  GPIO_InitStruct.Pull = GPIO_NOPULL;
  GPIO_InitStruct.Speed = GPIO_SPEED_FREQ_LOW;
  HAL_GPIO_Init(GPIOF, &GPIO_InitStruct);

  /*Configure GPIO pin : LCD_A0_RS_Pin */
  GPIO_InitStruct.Pin = LCD_A0_RS_Pin;
  GPIO_InitStruct.Mode = GPIO_MODE_AF_PP;
  GPIO_InitStruct.Pull = GPIO_NOPULL;
  GPIO_InitStruct.Speed = GPIO_SPEED_FREQ_VERY_HIGH;
  GPIO_InitStruct.Alternate = GPIO_AF12_FMC;
  HAL_GPIO_Init(LCD_A0_RS_GPIO_Port, &GPIO_InitStruct);

  /*Configure GPIO pin : ARD_D9_Pin */
  GPIO_InitStruct.Pin = ARD_D9_Pin;
  GPIO_InitStruct.Mode = GPIO_MODE_AF_PP;
  GPIO_InitStruct.Pull = GPIO_NOPULL;
  GPIO_InitStruct.Speed = GPIO_SPEED_FREQ_LOW;
  GPIO_InitStruct.Alternate = GPIO_AF1_TIM1;
  HAL_GPIO_Init(ARD_D9_GPIO_Port, &GPIO_InitStruct);

  /*Configure GPIO pin : PC7 */
  GPIO_InitStruct.Pin = GPIO_PIN_7;
  GPIO_InitStruct.Mode = GPIO_MODE_AF_PP;
  GPIO_InitStruct.Pull = GPIO_NOPULL;
  GPIO_InitStruct.Speed = GPIO_SPEED_FREQ_VERY_HIGH;
  GPIO_InitStruct.Alternate = GPIO_AF9_FMC;
  HAL_GPIO_Init(GPIOC, &GPIO_InitStruct);

  /*Configure GPIO pin : LCD_PWR_ON_Pin */
  GPIO_InitStruct.Pin = LCD_PWR_ON_Pin;
  GPIO_InitStruct.Mode = GPIO_MODE_OUTPUT_PP;
  GPIO_InitStruct.Pull = GPIO_NOPULL;
  GPIO_InitStruct.Speed = GPIO_SPEED_FREQ_LOW;
  HAL_GPIO_Init(LCD_PWR_ON_GPIO_Port, &GPIO_InitStruct);

  /*Configure GPIO pins : LCD_CTP_INT_Pin UCPD_FLT_Pin */
  GPIO_InitStruct.Pin = LCD_CTP_INT_Pin|UCPD_FLT_Pin;
  GPIO_InitStruct.Mode = GPIO_MODE_IT_RISING;
  GPIO_InitStruct.Pull = GPIO_NOPULL;
  HAL_GPIO_Init(GPIOG, &GPIO_InitStruct);

  /*Configure GPIO pin : PF10 */
  GPIO_InitStruct.Pin = GPIO_PIN_10;
  GPIO_InitStruct.Mode = GPIO_MODE_AF_PP;
  GPIO_InitStruct.Pull = GPIO_NOPULL;
  GPIO_InitStruct.Speed = GPIO_SPEED_FREQ_VERY_HIGH;
  GPIO_InitStruct.Alternate = GPIO_AF9_OCTOSPI1;
  HAL_GPIO_Init(GPIOF, &GPIO_InitStruct);

  /*Configure GPIO pin : PG6 */
  GPIO_InitStruct.Pin = GPIO_PIN_6;
  GPIO_InitStruct.Mode = GPIO_MODE_AF_PP;
  GPIO_InitStruct.Pull = GPIO_NOPULL;
  GPIO_InitStruct.Speed = GPIO_SPEED_FREQ_VERY_HIGH;
  GPIO_InitStruct.Alternate = GPIO_AF10_OCTOSPI1;
  HAL_GPIO_Init(GPIOG, &GPIO_InitStruct);

  /*Configure GPIO pin : PC2 */
  GPIO_InitStruct.Pin = GPIO_PIN_2;
  GPIO_InitStruct.Mode = GPIO_MODE_AF_PP;
  GPIO_InitStruct.Pull = GPIO_NOPULL;
  GPIO_InitStruct.Speed = GPIO_SPEED_FREQ_VERY_HIGH;
  GPIO_InitStruct.Alternate = GPIO_AF9_OCTOSPI1;
  HAL_GPIO_Init(GPIOC, &GPIO_InitStruct);

  /*Configure GPIO pins : PD12 PD13 */
  GPIO_InitStruct.Pin = GPIO_PIN_12|GPIO_PIN_13;
  GPIO_InitStruct.Mode = GPIO_MODE_AF_PP;
  GPIO_InitStruct.Pull = GPIO_NOPULL;
  GPIO_InitStruct.Speed = GPIO_SPEED_FREQ_VERY_HIGH;
  GPIO_InitStruct.Alternate = GPIO_AF9_OCTOSPI1;
  HAL_GPIO_Init(GPIOD, &GPIO_InitStruct);

  /*Configure GPIO pin : PC0 */
  GPIO_InitStruct.Pin = GPIO_PIN_0;
  GPIO_InitStruct.Mode = GPIO_MODE_AF_PP;
  GPIO_InitStruct.Pull = GPIO_NOPULL;
  GPIO_InitStruct.Speed = GPIO_SPEED_FREQ_VERY_HIGH;
  GPIO_InitStruct.Alternate = GPIO_AF10_OCTOSPI1;
  HAL_GPIO_Init(GPIOC, &GPIO_InitStruct);

  /*Configure GPIO pin : STMOD_18_Pin */
  GPIO_InitStruct.Pin = STMOD_18_Pin;
  GPIO_InitStruct.Mode = GPIO_MODE_IT_RISING;
  GPIO_InitStruct.Pull = GPIO_NOPULL;
  HAL_GPIO_Init(STMOD_18_GPIO_Port, &GPIO_InitStruct);

  /*Configure GPIO pin : PD11 */
  GPIO_InitStruct.Pin = GPIO_PIN_11;
  GPIO_InitStruct.Mode = GPIO_MODE_AF_PP;
  GPIO_InitStruct.Pull = GPIO_NOPULL;
  GPIO_InitStruct.Speed = GPIO_SPEED_FREQ_LOW;
  GPIO_InitStruct.Alternate = GPIO_AF2_SAI1;
  HAL_GPIO_Init(GPIOD, &GPIO_InitStruct);

  /*Configure GPIO pins : ARD_A1_Pin ARD_A2_Pin ARD_A4_Pin ARD_A3_Pin */
  GPIO_InitStruct.Pin = ARD_A1_Pin|ARD_A2_Pin|ARD_A4_Pin|ARD_A3_Pin;
  GPIO_InitStruct.Mode = GPIO_MODE_ANALOG;
  GPIO_InitStruct.Pull = GPIO_NOPULL;
  HAL_GPIO_Init(GPIOA, &GPIO_InitStruct);

  /*Configure GPIO pin : ARD_D11_Pin */
  GPIO_InitStruct.Pin = ARD_D11_Pin;
  GPIO_InitStruct.Mode = GPIO_MODE_AF_PP;
  GPIO_InitStruct.Pull = GPIO_NOPULL;
  GPIO_InitStruct.Speed = GPIO_SPEED_FREQ_LOW;
  GPIO_InitStruct.Alternate = GPIO_AF5_SPI2;
  HAL_GPIO_Init(ARD_D11_GPIO_Port, &GPIO_InitStruct);

  /*Configure GPIO pin : PDM_SAI1_SD3_Pin */
  GPIO_InitStruct.Pin = PDM_SAI1_SD3_Pin;
  GPIO_InitStruct.Mode = GPIO_MODE_AF_PP;
  GPIO_InitStruct.Pull = GPIO_NOPULL;
  GPIO_InitStruct.Speed = GPIO_SPEED_FREQ_LOW;
  GPIO_InitStruct.Alternate = GPIO_AF2_SAI1;
  HAL_GPIO_Init(PDM_SAI1_SD3_GPIO_Port, &GPIO_InitStruct);

  /*Configure GPIO pin : ARD_D10_Pin */
  GPIO_InitStruct.Pin = ARD_D10_Pin;
  GPIO_InitStruct.Mode = GPIO_MODE_AF_PP;
  GPIO_InitStruct.Pull = GPIO_NOPULL;
  GPIO_InitStruct.Speed = GPIO_SPEED_FREQ_LOW;
  GPIO_InitStruct.Alternate = GPIO_AF5_SPI2;
  HAL_GPIO_Init(ARD_D10_GPIO_Port, &GPIO_InitStruct);

  /*Configure GPIO pin : PB1 */
  GPIO_InitStruct.Pin = GPIO_PIN_1;
  GPIO_InitStruct.Mode = GPIO_MODE_AF_PP;
  GPIO_InitStruct.Pull = GPIO_NOPULL;
  GPIO_InitStruct.Speed = GPIO_SPEED_FREQ_VERY_HIGH;
  GPIO_InitStruct.Alternate = GPIO_AF6_OCTOSPI1;
  HAL_GPIO_Init(GPIOB, &GPIO_InitStruct);

  /*Configure GPIO pins : ARD_A5_Pin IBUS_SENSE_Pin STMOD_13_Pin VBUS_SENSE_Pin */
  GPIO_InitStruct.Pin = ARD_A5_Pin|IBUS_SENSE_Pin|STMOD_13_Pin|VBUS_SENSE_Pin;
  GPIO_InitStruct.Mode = GPIO_MODE_ANALOG;
  GPIO_InitStruct.Pull = GPIO_NOPULL;
  HAL_GPIO_Init(GPIOF, &GPIO_InitStruct);

  /*Configure GPIO pins : LCD_D6_Pin LCD_D11_Pin LCD_D12_Pin LCD_D5_Pin
                           LCD_D8_Pin LCD_D10_Pin PE7 LCD_D7_Pin
                           LCD_D9_Pin */
  GPIO_InitStruct.Pin = LCD_D6_Pin|LCD_D11_Pin|LCD_D12_Pin|LCD_D5_Pin
                          |LCD_D8_Pin|LCD_D10_Pin|GPIO_PIN_7|LCD_D7_Pin
                          |LCD_D9_Pin;
  GPIO_InitStruct.Mode = GPIO_MODE_AF_PP;
  GPIO_InitStruct.Pull = GPIO_NOPULL;
  GPIO_InitStruct.Speed = GPIO_SPEED_FREQ_VERY_HIGH;
  GPIO_InitStruct.Alternate = GPIO_AF12_FMC;
  HAL_GPIO_Init(GPIOE, &GPIO_InitStruct);

  /*Configure GPIO pins : STMOD_9_MISOs_Pin STMOD_12_RST_Pin */
  GPIO_InitStruct.Pin = STMOD_9_MISOs_Pin|STMOD_12_RST_Pin;
  GPIO_InitStruct.Mode = GPIO_MODE_AF_PP;
  GPIO_InitStruct.Pull = GPIO_NOPULL;
  GPIO_InitStruct.Speed = GPIO_SPEED_FREQ_LOW;
  GPIO_InitStruct.Alternate = GPIO_AF5_SPI5;
  HAL_GPIO_Init(GPIOH, &GPIO_InitStruct);

  /*Configure GPIO pins : ARD_D6_Pin ARD_D5_Pin */
  GPIO_InitStruct.Pin = ARD_D6_Pin|ARD_D5_Pin;
  GPIO_InitStruct.Mode = GPIO_MODE_AF_PP;
  GPIO_InitStruct.Pull = GPIO_NOPULL;
  GPIO_InitStruct.Speed = GPIO_SPEED_FREQ_LOW;
  GPIO_InitStruct.Alternate = GPIO_AF2_TIM5;
  HAL_GPIO_Init(GPIOH, &GPIO_InitStruct);

  /*Configure GPIO pins : UCPD_CC2_Pin ARD_A0_Pin UCPD_CC1_Pin */
  GPIO_InitStruct.Pin = UCPD_CC2_Pin|ARD_A0_Pin|UCPD_CC1_Pin;
  GPIO_InitStruct.Mode = GPIO_MODE_ANALOG;
  GPIO_InitStruct.Pull = GPIO_NOPULL;
  HAL_GPIO_Init(GPIOB, &GPIO_InitStruct);

  /*Configure GPIO pins : PH3 PH2 */
  GPIO_InitStruct.Pin = GPIO_PIN_3|GPIO_PIN_2;
  GPIO_InitStruct.Mode = GPIO_MODE_AF_PP;
  GPIO_InitStruct.Pull = GPIO_NOPULL;
  GPIO_InitStruct.Speed = GPIO_SPEED_FREQ_VERY_HIGH;
  GPIO_InitStruct.Alternate = GPIO_AF9_OCTOSPI1;
  HAL_GPIO_Init(GPIOH, &GPIO_InitStruct);

  /*Configure GPIO pin : PB2 */
  GPIO_InitStruct.Pin = GPIO_PIN_2;
  GPIO_InitStruct.Mode = GPIO_MODE_AF_PP;
  GPIO_InitStruct.Pull = GPIO_NOPULL;
  GPIO_InitStruct.Speed = GPIO_SPEED_FREQ_VERY_HIGH;
  GPIO_InitStruct.Alternate = GPIO_AF10_OCTOSPI1;
  HAL_GPIO_Init(GPIOB, &GPIO_InitStruct);

}

/* USER CODE BEGIN 4 */
//void HAL_TIM_PeriodElapsedCallback(TIM_HandleTypeDef *htim)
//{
//    if (htim->Instance == TIM1) {
//        HAL_IncTick();
//    }
//}

//static void MX_CRYP_Init(void)
//{
//    hcryp.Instance = CRYP;
//    hcryp.Init.DataType = CRYP_DATATYPE_32B;
//    hcryp.Init.pKey = (uint32_t *)pKeyCRYP;
//    hcryp.Init.Algorithm = CRYP_TDES_ECB;
//    hcryp.Init.DataWidthUnit = CRYP_DATAWIDTHUNIT_WORD;
//    if (HAL_CRYP_Init(&hcryp) != HAL_OK) {
//        Error_Handler();
//    }
//}

/* USER CODE END 4 */

void HAL_TIM_PeriodElapsedCallback(TIM_HandleTypeDef *htim)
{
  if (htim->Instance == TIM6)
  {
    HAL_IncTick();
  }
}

void Error_Handler(void)
{
  /* USER CODE BEGIN Error_Handler_Debug */
  /* User can add his own implementation to report the HAL error return state */
  __disable_irq();

  BSP_LED_On(LED_RED);
  while (1)
  {
  }
  /* USER CODE END Error_Handler_Debug */
}
